# AT32F423 register map
Vendor: Keil; Series: AT32F423; File version: 1.0
CPU: CM4 r0p1, little endian, no MPU, FPU, 4 interrupt priority bits
Registers are 32-bit, read-write, reset 0x0 unless marked. A register's access mark holds for its fields unless they carry their own. Offsets are from the block's base; [hi:lo] are bit positions; 'fields as' and 'values as' point back to an identical list; <NAME> marks a mode.

## I2C1 — Inter-integrated circuit
Base 0x40005400
Same registers: I2C2 0x40005800, I2C3 0x40005C00
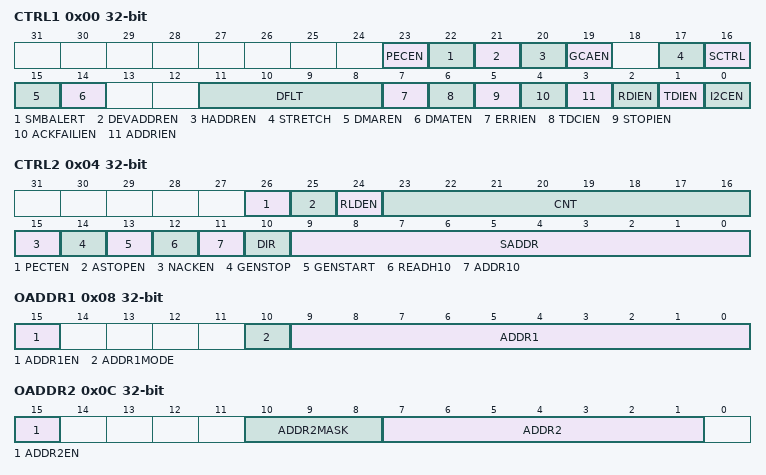
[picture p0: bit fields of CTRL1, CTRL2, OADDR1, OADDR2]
0x00 CTRL1 — Control register 1
  [23] PECEN — PEC calculation enable
    on read: 0=Disabled (PEC calculation is disabled); 1=Enabled (PEC calculation is enabled) | on write: 0=Disable PEC calculation; 1=Enable PEC calculation
  [22] SMBALERT — SMBus alert enable / pin set
    0=HighDisabled (Slave SMBus alert pin high / Master SMBus alert disabled); 1=LowEnabled (Slave SMBus alert pin low, response address 0001100x / Master SMBus alert enabled)
  [21] DEVADDREN — SMBus device default address enable
    0=Disabled (SMBus device default address disabled); 1=Enabled (SMBus device default address enabled, response with default address 1100001x)
  [20] HADDREN — SMBus host address enable
    0=Disabled (SMBus host address disabled); 1=Enabled (SMBus host address enabled, response with host address 0001000x)
  [19] GCAEN — General call address enable
    on read: 0=Disabled (General call address is disabled); 1=Enabled (General call address is enabled, response 0000000x) | on write: 0=Disable general call address; 1=Enable general call address, response 0000000x
  [17] STRETCH — Clock stretching mode
    on read: 0=Disabled (Clock stretching mode is disabled); 1=Enabled (Clock stretching mode is enabled) | on write: 0=Disable clock stretching mode; 1=Enable clock stretching mode
  [16] SCTRL — Slave receiving data control
    0=Disabled (Slave receive data control disabled); 1=Enabled (Slave receive data control enabled)
  [15] DMAREN — DMA receive data request enable
    0=Disabled (DMA receive data request disabled); 1=Enabled (DMA receive data request enabled)
  [14] DMATEN — DMA Transmit data request enable
    0=Disabled (DMA transmit data request disabled); 1=Enabled (DMA transmit data request enabled)
  [11:8] DFLT — Digital filter value
  [7] ERRIEN — Error interrupts enable
    on read: 0=Disabled (Error interrupt is disabled); 1=Enabled (Error interrupt is enabled) | on write: 0=Disable error interrupt; 1=Enable error interrupt
  [6] TDCIEN — Transfer data complete interrupt enable
    on read: 0=Disabled (Data transfer complete interrupt is disabled); 1=Enabled (Data transfer complete interrupt is enabled) | on write: 0=Disable Data transfer complete interrupt; 1=Enable Data transfer complete interrupt
  [5] STOPIEN — Stop generation complete interrupt enable
    on read: 0=Disabled (Stop generation complete interrupt is disabled); 1=Enabled (Stop generation complete interrupt is enabled) | on write: 0=Disable Stop generation complete interrupt; 1=Enable Stop generation complete interrupt
  [4] ACKFAILIEN — Acknowledge fail interrupt enable
    on read: 0=Disabled (Acknowledge failure interrupt is disabled); 1=Enabled (Acknowledge failure interrupt is enabled) | on write: 0=Disable Acknowledge failure interrupt; 1=Enable Acknowledge failure interrupt
  [3] ADDRIEN — Address match interrupt enable
    on read: 0=Disabled (Address match interrupt is disabled); 1=Enabled (Address match interrupt is enabled) | on write: 0=Disable Address match interrupt; 1=Enable Address match interrupt
  [2] RDIEN — Receive data interrupt enable
    on read: 0=Disabled (Data receive interrupt is disabled); 1=Enabled (Data receive interrupt is enabled) | on write: 0=Disable Data receive interrupt; 1=Enable Data receive interrupt
  [1] TDIEN — Transmit data interrupt enable
    on read: 0=Disabled (Data transmit interrupt is disabled); 1=Enabled (Data transmit interrupt is enabled) | on write: 0=Disable Data transmit interrupt; 1=Enable Data transmit interrupt
  [0] I2CEN — I2C peripheral enable
    on read: 0=Disabled (I2C peripheral is disabled); 1=Enabled (I2C peripheral is enabled) | on write: 0=Disable I2C peripheral; 1=Enable I2C peripheral
0x04 CTRL2 — Control register 2
  [26] PECTEN — Request PEC transmission enable
    on read: 0=Disabled (PEC transmission is disabled); 1=Enabled (PEC transmission is enabled) | on write: 0=Disable PEC transmission; 1=Enable PEC transmission
  [25] ASTOPEN — Automatically send stop condition enable
    0=Disabled (Automatic end mode disabled, software sends STOP condition); 1=Enabled (Automatic end mode enabled. automatically send STOP condition)
  [24] RLDEN — Send data reload mode enable
    0=Disabled (Send data reload mode disabled); 1=Enabled (Send data reload mode enabled)
  [23:16] CNT — Transmit data counter
  [15] NACKEN — Not acknowledge enable
    0=Disabled (NACK generation disabled); 1=Enabled (NACK generation enabled)
  [14] GENSTOP write-1-sets — Generate stop condition
    on write: 1=Stop (Generate stop condition in master mode)
  [13] GENSTART write-1-sets — Generate start condition
    on write: 1=Start (Generate start condition in master mode)
  [12] READH10 — 10-bit address header read enable
    0=Disabled (10-bit address header read disabled); 1=Enabled (10-bit address header read enabled)
  [11] ADDR10 — Host send 10-bit address mode enable
    0=Mode7Bit (7-bit address mode); 1=Mode10Bit (10-bit address mode)
  [10] DIR — Master data transmission direction
    0=Transmit (Master transmits data to slave); 1=Receive (Master receives data from slave)
  [9:0] SADDR — Slave address
0x08 OADDR1 — Own address register 1
  [15] ADDR1EN — Own address 1 enable
    0=Disabled (Own address 1 disabled); 1=Enabled (Own address 1 enabled)
  [10] ADDR1MODE — Own Address mode
    values as CTRL2.ADDR10
  [9:0] ADDR1 — Interface address
0x0C OADDR2 — Own address register 2
  [15] ADDR2EN — Own address 2 enable
    0=Disabled (Own address 2 disabled); 1=Enabled (Own address 2 enabled)
  [10:8] ADDR2MASK — Own address 2-bit mask
  [7:1] ADDR2 — Own address 2
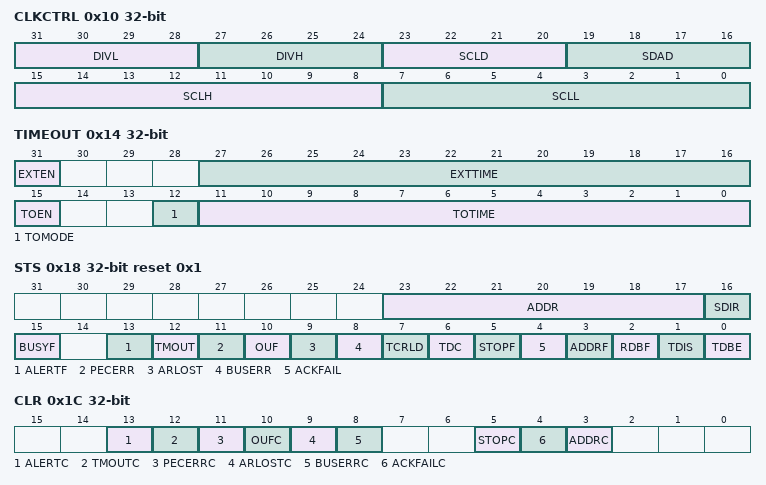
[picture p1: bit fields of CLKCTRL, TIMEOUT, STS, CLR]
0x10 CLKCTRL — Clock contorl register
  [31:28] DIVL — Clock prescaler low. DIV = (DIVH << 4) + DIVL
  [27:24] DIVH — Clock prescaler high. DIV = (DIVH << 4) + DIVL
  [23:20] SCLD — SCL delay. TSCLD = (SCLD + 1) x (DIV + 1) x TI2C_CLK
  [19:16] SDAD — SDA delay. TSDAD = (SDAD + 1) x (DIV + 1) x TI2C_CLK
  [15:8] SCLH — SCL high level. TSCLH = (SCLH + 1) x (DIV + 1) x TI2C_CLK
  [7:0] SCLL — SCL low level. TSCLL = (SCLL + 1) x (DIV + 1) x TI2C_CLK
0x14 TIMEOUT
  [31] EXTEN — Cumulative clock low extend timeout enable
    0=Disabled (Cumulative clock low extend timeout disabled); 1=Enabled (Cumulative clock low extend timeout enabled)
  [27:16] EXTTIME — Cumulative clock low extend timeout value. (EXTTIME + 1) x 2048 x TI2C_CLK.
  [15] TOEN — Detect clock low/high timeout enable
    0=Disabled (Clock timeout detection disabled); 1=Enabled (Clock timeout detection enabled)
  [12] TOMODE — Clock timeout detection mode
    0=LowLevel (Clock low level detection timeout); 1=HighLevel (Clock high level detection timeout)
  [11:0] TOTIME — Clock timeout. For low level: (TOTIME + 1) x 2048 x TI2C_CLK. For high level: (TOTIME + 1) x 4 x TI2C_CLK.
0x18 STS reset 0x1 — Interrupt and Status register
  [23:17] ADDR ro — Slave address matching value
  [16] SDIR ro — Slave data transmit direction
    0=Receive (Data byte received from slave); 1=Transmit (Data byte transmitted to slave)
  [15] BUSYF ro — Bus busy
    0=Idle (I2C bus is idle); 1=Busy (I2C bus is busy. Start condition was set)
  [13] ALERTF ro — SMBus alert flag
    0=NoAlert (No SMBus alert); 1=Alert (SMBus alert occurred)
  [12] TMOUT ro — SMBus timeout flag
    0=NoTimeout (No SMBus timeout occurred); 1=Timeout (SMBus timeout occurred)
  [11] PECERR ro — PEC receive error flag
    0=NoError (No PEC error); 1=Error (PEC error in reception or transmission)
  [10] OUF ro — Overflow or underflow flag
    0=No overrun/underrun occurred; 1=Overrun/underrun occurred
  [9] ARLOST ro — Arbitration lost flag
    0=NoLost (No arbitration lost detected); 1=Lost (Arbitration lost detected)
  [8] BUSERR ro — Bus error flag
    0=NoError (No bus error detected); 1=Error (Bus error detected)
  [7] TCRLD ro — Transmission is complete, waiting to load data
    0=NotComplete (Data transfer not complete yet); 1=Complete (Data transfer complete, waiting for data load)
  [6] TDC ro — Transmit data complete flag
    0=NotComplete (Data transfer not complete yet); 1=Complete (Data transfer complete, data loaded)
  [5] STOPF ro — Stop condition generation complete flag
    0=No Stop condition detected; 1=Stop condition detected
  [4] ACKFAIL ro — Acknowledge failure flag
    0=NoFailure (No acknowledge failure); 1=Failure (Acknowledge failure)
  [3] ADDRF ro — 0~7 bit address match flag
    0=NoMatch (No address matched); 1=Matched (Address matched)
  [2] RDBF ro — Receive data buffer full flag
    0=Empty (Data register empty); 1=HasData (Data register not empty)
  [1] TDIS write-1-sets — Send interrupt status
    on read: 0=NotEmpty (Data has been written to the I2C_TXDT); 1=Empty (Data has been sent from the I2C_TXDT to the shift register. I2C_TXDT become empty, and thus the to-be- transferred data must be written to the I2C_TXDT) | on write: 1=Tdis (Write 1 to generate TDIS event when clock stretching is disabled.)
  [0] TDBE write-1-clears — Transmit data buffer empty flag
    on read: 0=NotEmpty (Data register not empty); 1=Empty (Data register empty) | on write: 1=Clear (Write 1 to clear TDBE flag when clock stretching is disabled.)
0x1C CLR wo — Interrupt clear register
  [all] fields
    1=Clear (Write 1 to clear flag)
  [13] ALERTC write-1-clears — Clear SMBus alert flag
  [12] TMOUTC write-1-clears — Clear SMBus timeout flag
  [11] PECERRC write-1-clears — Clear PEC receive error flag
  [10] OUFC write-1-clears — Clear overload / underload flag
  [9] ARLOSTC write-1-clears — Clear arbitration lost flag
  [8] BUSERRC write-1-clears — Clear bus error flag
  [5] STOPC write-1-clears — Clear stop condition generation complete flag
  [4] ACKFAILC write-1-clears — Clear acknowledge failure flag
  [3] ADDRC write-1-clears — Clear 0~7 bit address match flag
0x20 PEC ro
  [7:0] PECVAL — PEC value
0x24 RXDT ro — Receive data register
  [7:0] DT
0x28 TXDT — Transmit data register
  [7:0] DT
